VERSION ""

NS_ :

BS_:
BU_:
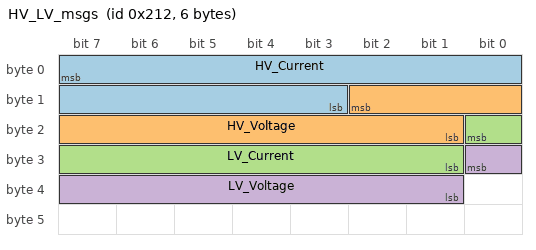
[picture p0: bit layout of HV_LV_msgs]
BO_ 530 HV_LV_msgs: 6 Vector__XXX
   SG_ HV_Current : 7|13@0+ (0.05,0) [0|20] "Amps" Vector__XXX
   SG_ HV_Voltage : 10|10@0+ (0.5,0) [0|500] "Volts" Vector__XXX
   SG_ LV_Current : 16|8@0+ (0.2,0) [0|50] "Amps" Vector__XXX
   SG_ LV_Voltage : 24|8@0+ (0.1,0) [0|30] "Volts" Vector__XXX

BO_ 778 AC_msgs: 7 Vector__XXX
   SG_ AC_Current : 7|12@0+ (0.2,0) [0|20] "Amps" Vector__XXX
   SG_ AC_Voltage : 11|8@0+ (2,0) [0|500] "Volts" Vector__XXX

BA_DEF_ BO_ "GenMsgBackgroundColor" STRING ;
BA_DEF_ BO_ "GenMsgForegroundColor" STRING ;
BA_DEF_DEF_ "GenMsgBackgroundColor" "#ffffff";
BA_DEF_DEF_ "GenMsgForegroundColor" "#000000";
